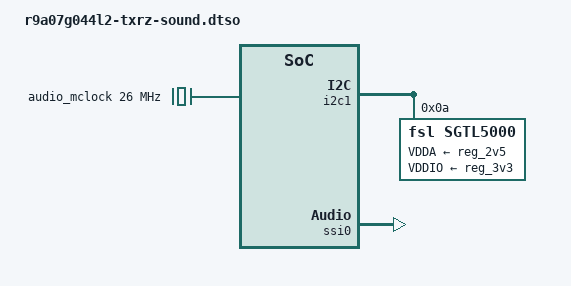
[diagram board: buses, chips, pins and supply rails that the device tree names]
// SPDX-License-Identifier: (GPL-2.0-only OR BSD-3-Clause)
/*
 * Copyright (C) 2023 Markus Bauer <MB@karo-electronics.com>
 */
/dts-v1/;
/plugin/;

&{/chosen} {
	overlays {
		txrz-sound;
	};
};

&{/} {
	audio_mclock: audio_mclock {
		compatible = "fixed-clock";
		#clock-cells = <0>;
		clock-frequency = <26000000>;
	};

	sound {
		compatible = "simple-audio-card";
		simple-audio-card,format = "i2s";
		simple-audio-card,bitclock-master = <&codec_dai>;
		simple-audio-card,frame-master = <&codec_dai>;
		simple-audio-card,mclk-fs = <256>;

		simple-audio-card,widgets =
			"Microphone", "Mic Jack",
			"Line", "Line In",
			"Line", "Line Out",
			"Headphone", "Headphone Jack";
		simple-audio-card,routing =
			"MIC_IN", "Mic Jack",
			"Mic Jack", "Mic Bias",
			"Headphone Jack", "HP_OUT";

		cpu_dai: simple-audio-card,cpu {
			sound-dai = <&ssi0>;
		};

		codec_dai: simple-audio-card,codec {
			sound-dai = <&sgtl5000>;
		};
	};
};

&i2c1 {
	sgtl5000: codec@a {
		compatible = "fsl,sgtl5000";
		#sound-dai-cells = <0>;
		reg = <0x0a>;
		VDDA-supply = <&reg_2v5>;
		VDDIO-supply = <&reg_3v3>;
		clocks = <&audio_mclock>;
		status = "okay";
	};
};

&ssi0 {
	status = "okay";
};
